# AM13E230x register map
Vendor: Texas Instruments; File version: Revised: 2025-12-26 17:30:06
CPU: CM33 r0p0, little endian, MPU, FPU, 4 interrupt priority bits
Registers are 32-bit, read-write, reset 0x0 unless marked. A register's access mark holds for its fields unless they carry their own. Offsets are from the block's base; [hi:lo] are bit positions; lines under a group give offsets from that group; {n}, {i} and the like mark numbered series; <NAME> marks a mode.

## UC0_SPI — PERIPHERALREGION
Base 0x40618000
Same registers: UC1_SPI 0x40619000, UC3_SPI 0x40658000, UC4_SPI 0x40659000
0x00 CLKDIV — Clock Divider
  [2:0] RATIO — Selects divide ratio of module clock
    0=DIV_BY_1 (Do not divide clock source); {v}=DIV_BY_{v+1} (Divide clock source by {v+1}) (v=1..7)
0x08 CLKSEL — Clock Select for Ultra Low Power peripherals
  [3] BUSCLK_SEL — Selects buscclk as clock source if enabled
    0=DISABLE (Does not select this clock as a source); 1=ENABLE (Select this clock as a source)
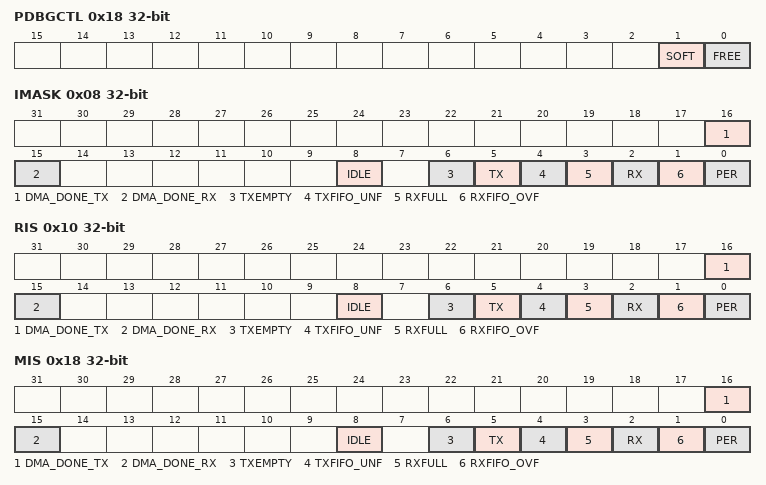
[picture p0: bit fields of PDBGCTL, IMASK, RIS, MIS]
0x18 PDBGCTL — Peripheral Debug Control
  [1] SOFT — Soft halt boundary control. This function is only available, if [FREE] is set to 'STOP'
    0=DEPRECATED (Not supported); 1=DELAYED (The peripheral blocks the debug freeze until it has reached a boundary where it can resume without corruption)
  [0] FREE — Free run control
    0=STOP (The peripheral freezes functionality while the Core Halted input is asserted and resumes when it is deasserted.); 1=RUN (The peripheral ignores the state of the Core Halted input)
0x20 CPU_INT group
  0x00 IIDX ro — Interrupt Index Register
    [7:0] STAT — Interrupt index status
      0=NO_INTR (No interrupt pending); 1=PER_EVT (Transmit Parity Event/interrupt pending); 2=RXFIFO_OFV_EVT (RX FIFO Overflow Event/interrupt pending); 3=RX_EVT (Receive interrupt); 4=RXFULL_EVT (RX FIFO Full Interrupt); 5=TXFIFO_UNF_EVT (TX FIFO underflow interrupt); 6=TX_EVT (Transmit Event); 7=TX_EMPTY (Transmit Buffer Empty Event/interrupt pending); 9=IDLE_EVT (End of Transmit Event/interrupt pending); 10=RTOUT_EVT (SPI receive time-out interrupt); 16=DMA_DONE_RX (DMA DONE on RX); 17=DMA_DONE_TX (DMA DONE on TX); 19=DMA_PREIRQ_RX (DMA PRE IRQ RX INTERRUPT); 20=DMA_PREIRQ_TX (DMA PRE IRQ TX INTERRUPT); 21=LTOUT (SPI line time-out interrupt)
  0x08 IMASK — Interrupt mask
    [16] DMA_DONE_TX — Enable DMA Done on TX Event Channel Interrupt
    [15] DMA_DONE_RX — Enable DMA Done on RX Event Channel Interrupt
    [8] IDLE — SPI in Idle mode
    [6] TXEMPTY — Transmit FIFO Empty interrupt mask
    [5] TX — Transmit event. When FIFO is present, this bit is set when FIFO threshold is reached. When FIFO is not used, this bit is set when transmit buffer is empty.
    [4] TXFIFO_UNF — TX FIFO underflow interrupt mask
    [3] RXFULL — RX FIFO Full Interrupt Mask
    [2] RX — Receive event. If FIFO is present, this bit is set when the programmed threshold is reached. When there is no FIFO, this bit is set when a frame is received
    [1] RXFIFO_OVF — RXFIFO overflow event
    [0] PER — Parity error event
  0x10 RIS ro — Raw interrupt status
    [16] DMA_DONE_TX — DMA Done on TX Event Channel Interrupt
    [15] DMA_DONE_RX — DMA Done on RX Event Channel Interrupt
    [8] IDLE — SPI in Idle mode
    [6] TXEMPTY — Transmit FIFO Empty interrupt mask
    [5] TX — Transmit Event
    [4] TXFIFO_UNF — TX FIFO Underflow Interrupt
    [3] RXFULL — RX FIFO Full Interrupt
    [2] RX — Receive event
    [1] RXFIFO_OVF — RXFIFO overflow event
    [0] PER — Parity error event
  0x18 MIS ro — Masked interrupt status
    [16] DMA_DONE_TX — Masked DMA Done on TX Event Channel Interrupt
    [15] DMA_DONE_RX — Masked DMA Done on RX Event Channel Interrupt
    [8] IDLE — SPI in Idle mode
    [6] TXEMPTY — Transmit FIFO Empty interrupt mask
    [5] TX — Masked transmit event
    [4] TXFIFO_UNF — TX FIFO underflow interrupt
    [3] RXFULL — RX FIFO Full Interrupt
    [2] RX — Masked Receive Event
    [1] RXFIFO_OVF — RXFIFO overflow event
    [0] PER — Parity error event
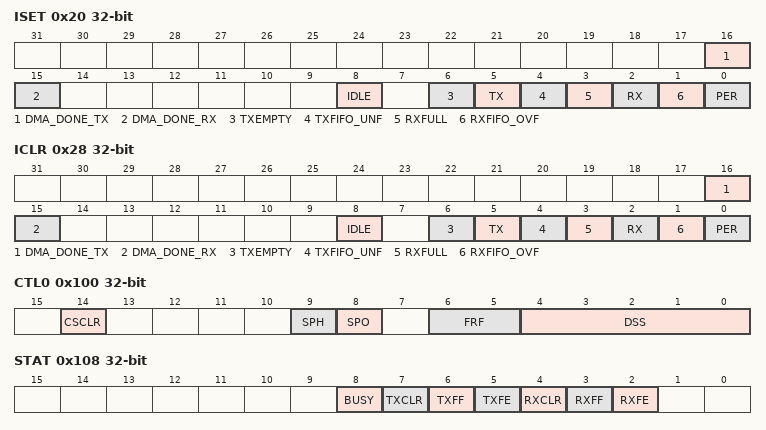
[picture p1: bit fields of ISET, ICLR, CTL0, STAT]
  0x20 ISET wo — Interrupt set
    [16] DMA_DONE_TX — Set DMA Done on TX Event Channel Interrupt
    [15] DMA_DONE_RX — Set DMA Done on RX Event Channel Interrupt
    [8] IDLE — SPI in Idle mode
    [6] TXEMPTY — Transmit FIFO Empty interrupt mask
    [5] TX — Transmit FIFO event
    [4] TXFIFO_UNF — Set TX FIFO Underflow Event
    [3] RXFULL — Set RX FIFO Full Event
    [2] RX — Receive FIFO event
    [1] RXFIFO_OVF — RXFIFO overflow event
    [0] PER — Parity error event
  0x28 ICLR wo — Interrupt clear
    [16] DMA_DONE_TX — Clear DMA Done on TX Event Channel Interrupt
    [15] DMA_DONE_RX — Clear DMA Done on RX Event Channel Interrupt
    [8] IDLE — SPI in Idle mode
    [6] TXEMPTY — Transmit FIFO Empty interrupt mask
    [5] TX — Transmit FIFO event
    [4] TXFIFO_UNF — Clear TXFIFO underflow event
    [3] RXFULL — Clear RX FIFO underflow event
    [2] RX — Receive FIFO event
    [1] RXFIFO_OVF — RXFIFO overflow event
    [0] PER — Parity error event
0x50 DMA_TRIG_RX group
  0x08 IMASK — Interrupt mask
    [2] RX — Receive FIFO event
  0x10 RIS ro — Raw interrupt status
    [2] RX — Receive FIFO event
  0x18 MIS ro — Masked interrupt status
    [2] RX — Receive FIFO event
  0x20 ISET wo — Interrupt set
    [2] RX — Receive FIFO event
0x80 DMA_TRIG_TX group
  0x08 IMASK — Interrupt mask
    [5] TX — Transmit FIFO event
  0x10 RIS ro — Raw interrupt status
    [5] TX — Transmit FIFO event
  0x18 MIS ro — Masked interrupt status
    [5] TX — Transmit FIFO event
  0x20 ISET wo — Interrupt set
    [5] TX — Transmit FIFO event
0xE4 INTCTL wo — Interrupt control register
  [0] INTEVAL — Writing a 1 to this field re-evaluates the interrupt sources.
    0=DISABLE (The interrupt or event line is disabled.); 1=EVAL (The interrupt or event line is in software mode. Software must clear the RIS.)
0x100 CTL0 — SPI control register 0
  [14] CSCLR — Clear on CS inactive
    0=DISABLE (Disable automatic clear of shift register when CS goes to disable.); 1=ENABLE (Enable automatic clear of shift register when CS goes to disable.)
  [9] SPH — CLKOUT phase
    0=FIRST (Data is captured on the first clock edge transition.); 1=SECOND (Data is captured on the second clock edge transition.)
  [8] SPO — CLKOUT polarity
    0=LOW (SPI produces a steady state LOW value on the CLKOUT); 1=HIGH (SPI produces a steady state HIGH value on the CLKOUT)
  [6:5] FRF — Frame format Select
    0=MOTOROLA_3WIRE (Motorola SPI frame format (3 wire mode)); 1=MOTOROLA_4WIRE (Motorola SPI frame format (4 wire mode)); 2=TI_SYNC (TI synchronous serial frame format)
  [4:0] DSS — Data Size Select.
    {v}=Data Size Select bits: {v+1} (v=3..15)
0x108 STAT ro — Status Register
  [8] BUSY
    0=IDLE (SPI is in idle mode.); 1=ACTIVE (SPI is currently transmitting and/or receiving data)
  [7] TXCLR — TX FIFO Clear Status
  [6] TXFF — Transmit FIFO Full The meaning of this bit depends on the state of the FEN bit in the CTL0 register.
  [5] TXFE — Transmit FIFO empty.
    0=NOT_EMPTY (Transmit FIFO is not empty.); 1=EMPTY (Transmit FIFO is empty.)
  [4] RXCLR — RX FIFO Clear Status
  [3] RXFF — Receive FIFO Full The meaning of this bit depends on the state of the FEN bit in the CTL0 register.
  [2] RXFE — Receive FIFO empty.
    0=NOT_EMPTY (Receive FIFO is not empty.); 1=EMPTY (Receive FIFO is empty.)
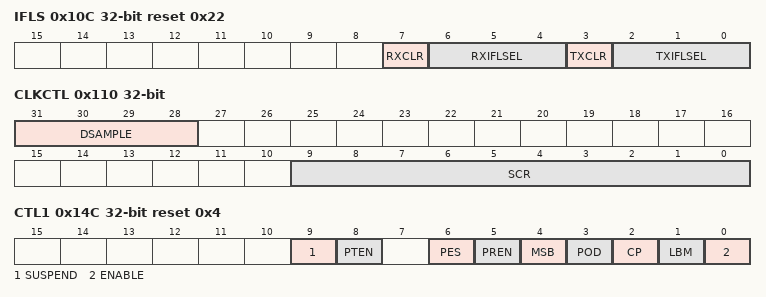
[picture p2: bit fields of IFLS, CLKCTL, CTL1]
0x10C IFLS reset 0x22 — Interrupt FIFO Level Select Register
  [7] RXCLR — RX FIFO CLEAR
    0=DISABLE (Disable FIFO clear); 1=ENABLE (Enable FIFO Clear)
  [6:4] RXIFLSEL — FIFO Level Select for generating events (interrupt/dma). Note: for undefined settings the default configuration is used.
    1=LVL_1_4 (RX FIFO >= 1/4 full); 2=LVL_1_2 (RX FIFO >= 1/2 full (default)); 3=LVL_3_4 (RX FIFO >= 3/4 full); 4=LVL_NOT_EMPTY (Opposite of empty); 5=LVL_FULL (RX FIFO is full); 6=LVL_ALMOST_FULL (RX_FIFO >= (MAX_FIFO_LEN -1)); 7=LVL_ALMOST_EMPTY (RX_FIFO <= 1)
  [3] TXCLR — RX FIFO Flush
    0=DISABLE (Disable FIFO clear); 1=ENABLE (Enable FIFO Clear)
  [2:0] TXIFLSEL — FIFO Level Select for generating events (interrupt/dma). Note: for undefined settings the default configuration is used.
    1=LVL_3_4 (TX FIFO <= 3/4 empty); 2=LVL_1_2 (TX FIFO <= 1/2 empty (default)); 3=LVL_1_4 (TX FIFO <= 1/4 empty); 4=LVL_NOT_FULL (Opposite of full); 5=LVL_EMPTY (TX FIFO is empty); 6=LVL_ALMOST_EMPTY (TX FIFO <= 1); 7=LVL_ALMOST_FULL (TX_FIFO >= (MAX_FIFO_LEN -1))
0x110 CLKCTL — Clock prescaler and divider register.
  [31:28] DSAMPLE — Delayed sampling.
  [9:0] SCR — Serial clock divider
0x120 TXDATA wo
  [15:0] DATA — Transmit Data
0x124 RXDATA ro
  [15:0] DATA — Received Data
0x14C CTL1 reset 0x4 — SPI control register 1
  [9] SUSPEND — Suspend external communication
    0=DISABLE (Functional mode resumed); 1=ENABLE (External communication suspended)
  [8] PTEN — Parity Transmit Enable
    0=DISABLE (Parity transmission is disabled); 1=ENABLE (Parity transmission is enabled)
  [6] PES — Even Parity Select
    0=DISABLE (Odd Parity mode); 1=ENABLE (Even Parity mode)
  [5] PREN — Parity Receive Enable
    0=DISABLE (Disable Parity receive function); 1=ENABLE (Enable Parity receive function)
  [4] MSB — MSB first select
    0=DISABLE (LSB first); 1=ENABLE (MSB first)
  [3] POD — Peripheral-mode: Data output disabled
    0=DISABLE (SPI can drive the POCI output in peripheral mode.); 1=ENABLE (SPI cannot drive the POCI output in peripheral mode.)
  [2] CP — Controller or peripheral mode select
    0=DISABLE (Select Peripheral mode); 1=ENABLE (Select Controller Mode)
  [1] LBM — Loop back mode enable
    0=DISABLE (Disable loopback mode); 1=ENABLE (Enable loopback mode)
  [0] ENABLE — SPI enable
